# STM32H7P4 register map
File version: 0.1
CPU: CM7 r1p2, little endian, MPU, FPU, 4 interrupt priority bits
Registers are 32-bit, read-write, reset 0x0 unless marked. A register's access mark holds for its fields unless they carry their own. Offsets are from the block's base; [hi:lo] are bit positions; {n}, {i} and the like mark numbered series.

## DLYBXS1 — DLYB register block
Base 0x52006000
Same registers: DLYBSD1 0x52008000
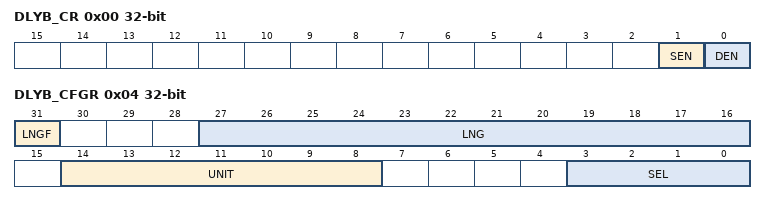
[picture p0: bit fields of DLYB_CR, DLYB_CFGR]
0x00 DLYB_CR — DLYB control register
  [1] SEN — Sampler length enable bit
    0=Sampler length and register access to UNIT[6:0] and SEL[3:0] disabled, output clock enabled; 1=Sampler length and register access to UNIT[6:0] and SEL[3:0] enabled, output clock disabled
  [0] DEN — Delay block enable bit
    0=DLYB disabled; 1=DLYB enabled
0x04 DLYB_CFGR — DLYB configuration register
  [31] LNGF ro — Length valid flag
    0=Length value in LNG is not valid; 1=Length value in LNG is valid
  [27:16] LNG ro — Delay line length value
  [14:8] UNIT — Delay of a unit delay cell.
  [3:0] SEL — Phase for the output clock.

## FMAC — FMAC register block
Base 0x48004800
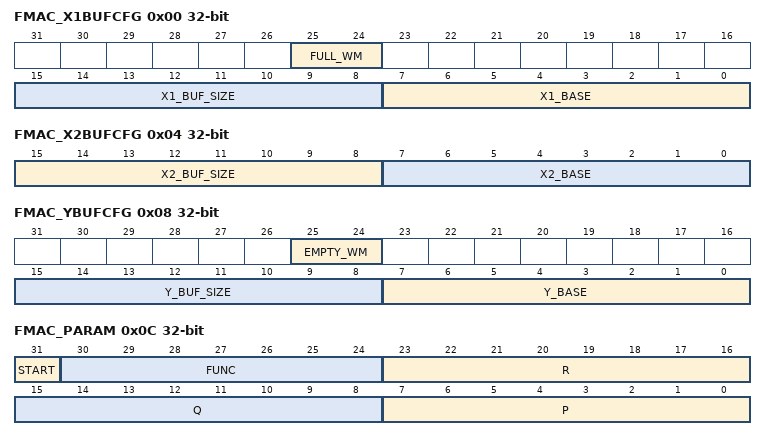
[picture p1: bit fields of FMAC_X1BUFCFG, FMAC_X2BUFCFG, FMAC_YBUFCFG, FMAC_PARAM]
0x00 FMAC_X1BUFCFG — FMAC X1 buffer configuration register
  [25:24] FULL_WM — Watermark for buffer full flag
    0=Threshold = 1; 1=Threshold = 2
  [15:8] X1_BUF_SIZE — Allocated size of X1 buffer in 16-bit words
  [7:0] X1_BASE — Base address of X1 buffer
0x04 FMAC_X2BUFCFG — FMAC X2 buffer configuration register
  [15:8] X2_BUF_SIZE — Size of X2 buffer in 16-bit words
  [7:0] X2_BASE — Base address of X2 buffer
0x08 FMAC_YBUFCFG — FMAC Y buffer configuration register
  [25:24] EMPTY_WM — Watermark for buffer empty flag
    0=Threshold = 1; 1=Threshold = 2
  [15:8] Y_BUF_SIZE — Size of Y buffer in 16-bit words
  [7:0] Y_BASE — Base address of Y buffer
0x0C FMAC_PARAM — FMAC parameter register
  [31] START — Enable execution
    0=Stop execution; 1=Start execution
  [30:24] FUNC — Function
    1=Load X1 buffer
  [23:16] R — Input parameter R.
  [15:8] Q — Input parameter Q.
  [7:0] P — Input parameter P.
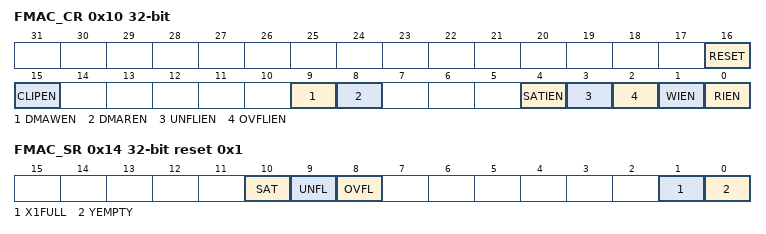
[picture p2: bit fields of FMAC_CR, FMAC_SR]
0x10 FMAC_CR — FMAC control register
  [16] RESET — Reset FMAC unit
    0=Reset inactive; 1=Reset active
  [15] CLIPEN — Enable clipping
    0=Clipping disabled; 1=Clipping enabled
  [9] DMAWEN — Enable DMA write channel requests
    0=Disable; 1=Enable
  [8] DMAREN — Enable DMA read channel requests
    0=Disable; 1=Enable
  [4] SATIEN — Enable saturation error interrupts
    0=Disabled; 1=Enabled
  [3] UNFLIEN — Enable underflow error interrupts
    0=Disabled; 1=Enabled
  [2] OVFLIEN — Enable overflow error interrupts
    0=Disabled; 1=Enabled
  [1] WIEN — Enable write interrupt
    0=Disabled; 1=Enabled
  [0] RIEN — Enable read interrupt
    0=Disabled; 1=Enabled
0x14 FMAC_SR ro reset 0x1 — FMAC status register
  [10] SAT — Saturation error flag
    0=No saturation detected; 1=Saturation detected
  [9] UNFL — Underflow error flag
    0=No underflow detected; 1=Underflow detected
  [8] OVFL — Overflow error flag
    0=No overflow detected; 1=Overflow detected
  [1] X1FULL — X1 buffer full flag
    0=X1 buffer not full; 1=X1 buffer full
  [0] YEMPTY — Y buffer empty flag
    0=Y buffer not empty; 1=Y buffer empty
0x18 FMAC_WDATA wo — FMAC write data register
  [15:0] WDATA — Write data
0x1C FMAC_RDATA ro — FMAC read data register
  [15:0] RDATA — Read data

## GPIOA — GPIO address block description
Base 0x58020000
Same registers: GPIOB 0x58020400, GPIOC 0x58020800, GPIOD 0x58020C00, GPIOE 0x58021000, GPIOF 0x58021400, GPIOG 0x58021800, GPIOH 0x58021C00, GPIOI 0x58022000
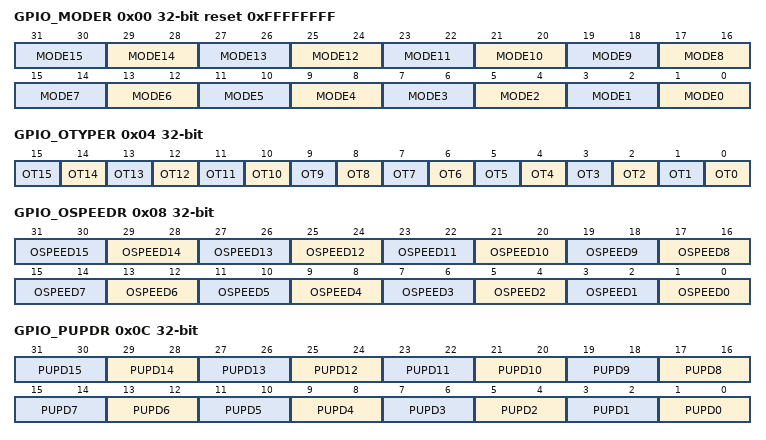
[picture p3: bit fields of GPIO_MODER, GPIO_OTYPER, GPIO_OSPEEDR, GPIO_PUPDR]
0x00 GPIO_MODER reset 0xFFFFFFFF — GPIO port mode register
  [all] fields
    0=Input mode; 1=General purpose output mode; 2=Alternate function mode; 3=Analog mode (reset state)
  [2n+1:2n] MODE{n} (n=0..15) — Port x configuration I/O pin y
0x04 GPIO_OTYPER — GPIO port output type register
  [all] fields
    0=Output push-pull (reset state); 1=Output open-drain
  [n] OT{n} (n=0..15) — Port x configuration I/O pin y
0x08 GPIO_OSPEEDR — GPIO port output speed register
  [all] fields
    0=Low speed; 1=Medium speed; 2=High speed; 3=Very-high speed
  [2n+1:2n] OSPEED{n} (n=0..15) — Port x configuration I/O pin y
0x0C GPIO_PUPDR — GPIO port pull-up/pull-down register
  [all] fields
    0=No pull-up, pull-down; 1=Pull-up; 2=Pull-down
  [2n+1:2n] PUPD{n} (n=0..15) — Port x configuration I/O pin y
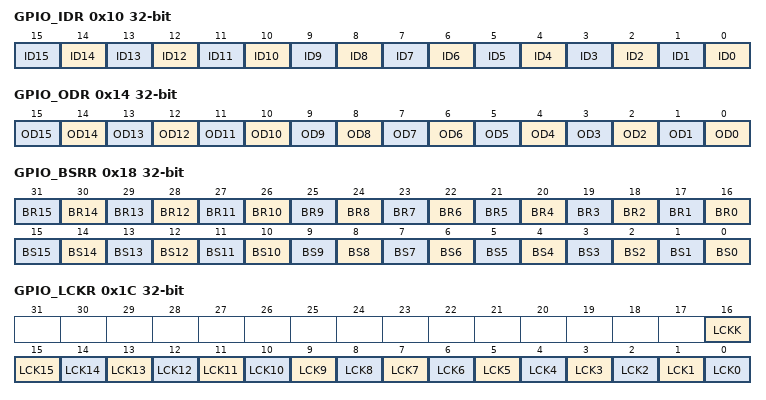
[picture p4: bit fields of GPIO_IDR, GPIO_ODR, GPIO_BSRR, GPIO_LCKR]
0x10 GPIO_IDR ro (reset mask 0xFFFF0000) — GPIO port input data register
  [n] ID{n} (n=0..15) — Port x input data I/O pin y
0x14 GPIO_ODR — GPIO port output data register
  [n] OD{n} (n=0..15) — Port output data I/O pin y
0x18 GPIO_BSRR wo — GPIO port bit set/reset register
  [n+16] BR{n} (n=0..15) — Port x reset I/O pin y
    0=No action on the corresponding ODy bit; 1=Resets the corresponding ODy bit
  [n] BS{n} (n=0..15) — Port x set I/O pin y
    0=No action on the corresponding ODy bit; 1=Sets the corresponding ODy bit
0x1C GPIO_LCKR — GPIO port configuration lock register
  [16] LCKK — Lock key
    0=Port configuration lock key not active; 1=Port configuration lock key active
  [n] LCK{n} (n=0..15) — Port x lock I/O pin y
    0=Port configuration not locked; 1=Port configuration locked
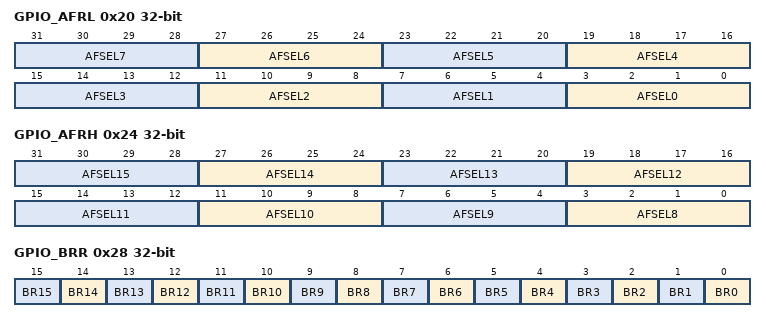
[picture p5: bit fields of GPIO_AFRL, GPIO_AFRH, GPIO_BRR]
0x20 GPIO_AFRL — GPIO alternate function low register
  [all] fields
    {v}=AF{v} (v=0..15)
  [4n+3:4n] AFSEL{n} (n=0..7) — Alternate function selection for port x I/O pin y
0x24 GPIO_AFRH — GPIO alternate function high register
  [all] fields
    {v}=AF{v} (v=0..15)
  [4n-29:4n-32] AFSEL{n} (n=8..15) — Alternate function selection for port x I/O pin y
0x28 GPIO_BRR wo — GPIO port bit reset register
  [all] fields
    0=No action on the corresponding ODy bit; 1=Reset the corresponding ODy bit
  [n] BR{n} (n=0..15) — Port x reset IO pin y
